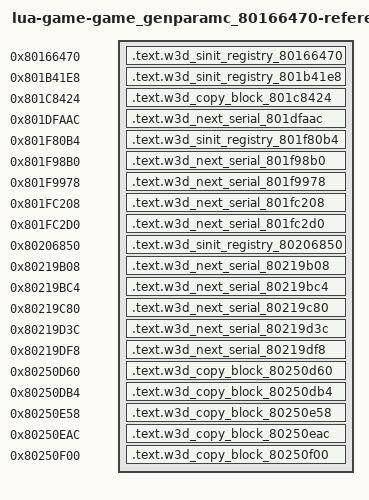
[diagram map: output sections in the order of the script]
/* Generated reference-only placements. All bodies are source-built. */
OUTPUT_FORMAT("elf32-powerpc")
OUTPUT_ARCH(powerpc)
ENTRY(w3d_sinit_registry_80166470)
_SDA_BASE_ = 0x804b2540;
_SDA2_BASE_ = 0x804c2540;
fn_801655fc = 0x801655fc;
fn_801b2ab8 = 0x801b2ab8;
fn_801f7b58 = 0x801f7b58;
fn_802058ac = 0x802058ac;
fn_8020fbd0 = 0x8020fbd0;
lbl_803e8904 = 0x803e8904;
lbl_803e8eec = 0x803e8eec;
lbl_803ea0f8 = 0x803ea0f8;
lbl_803ea1d8 = 0x803ea1d8;
lbl_80411ad8 = 0x80411ad8;
lbl_80419598 = 0x80419598;
lbl_804552b0 = 0x804552b0;
lbl_8045ce60 = 0x8045ce60;
lbl_8045e7b8 = 0x8045e7b8;
lbl_8045edf4 = 0x8045edf4;
SECTIONS {
  .text.w3d_sinit_registry_80166470 0x80166470 : { *(.text.w3d_sinit_registry_80166470) }
  .text.w3d_sinit_registry_801b41e8 0x801b41e8 : { *(.text.w3d_sinit_registry_801b41e8) }
  .text.w3d_copy_block_801c8424 0x801c8424 : { *(.text.w3d_copy_block_801c8424) }
  .text.w3d_next_serial_801dfaac 0x801dfaac : { *(.text.w3d_next_serial_801dfaac) }
  .text.w3d_sinit_registry_801f80b4 0x801f80b4 : { *(.text.w3d_sinit_registry_801f80b4) }
  .text.w3d_next_serial_801f98b0 0x801f98b0 : { *(.text.w3d_next_serial_801f98b0) }
  .text.w3d_next_serial_801f9978 0x801f9978 : { *(.text.w3d_next_serial_801f9978) }
  .text.w3d_next_serial_801fc208 0x801fc208 : { *(.text.w3d_next_serial_801fc208) }
  .text.w3d_next_serial_801fc2d0 0x801fc2d0 : { *(.text.w3d_next_serial_801fc2d0) }
  .text.w3d_sinit_registry_80206850 0x80206850 : { *(.text.w3d_sinit_registry_80206850) }
  .text.w3d_next_serial_80219b08 0x80219b08 : { *(.text.w3d_next_serial_80219b08) }
  .text.w3d_next_serial_80219bc4 0x80219bc4 : { *(.text.w3d_next_serial_80219bc4) }
  .text.w3d_next_serial_80219c80 0x80219c80 : { *(.text.w3d_next_serial_80219c80) }
  .text.w3d_next_serial_80219d3c 0x80219d3c : { *(.text.w3d_next_serial_80219d3c) }
  .text.w3d_next_serial_80219df8 0x80219df8 : { *(.text.w3d_next_serial_80219df8) }
  .text.w3d_copy_block_80250d60 0x80250d60 : { *(.text.w3d_copy_block_80250d60) }
  .text.w3d_copy_block_80250db4 0x80250db4 : { *(.text.w3d_copy_block_80250db4) }
  .text.w3d_copy_block_80250e58 0x80250e58 : { *(.text.w3d_copy_block_80250e58) }
  .text.w3d_copy_block_80250eac 0x80250eac : { *(.text.w3d_copy_block_80250eac) }
  .text.w3d_copy_block_80250f00 0x80250f00 : { *(.text.w3d_copy_block_80250f00) }
  /DISCARD/ : { *(.text*) *(.rodata*) *(.data*) *(.bss*) *(.sdata*) *(.sbss*) *(.comment) }
}
